# RA register map
Vendor: Renesas; Series: All Chips; File version: x.xx
Registers are 32-bit, read-write, reset 0x0 unless marked. A register's access mark holds for its fields unless they carry their own. Offsets are from the block's base; [hi:lo] are bit positions; {n}, {i} and the like mark numbered series.

## R_DEBUG — Debug Function
Base 0x4001B000
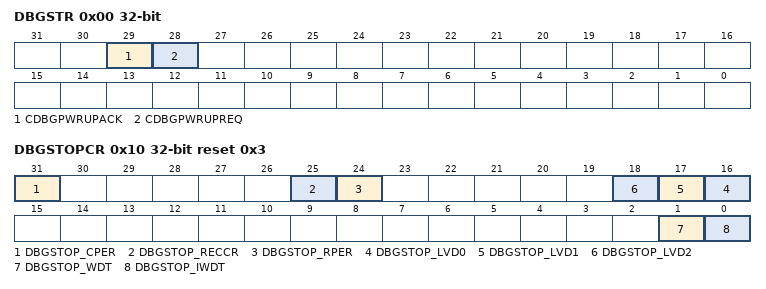
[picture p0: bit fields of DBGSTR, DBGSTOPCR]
0x00 DBGSTR ro — Debug Status Register
  [29] CDBGPWRUPACK — Debug power-up acknowledge
    0=Debug power-up request is not acknowledged; 1=Debug power-up request is acknowledged
  [28] CDBGPWRUPREQ — Debug power-up request
    0=0: OCD is not requesting debug power up; 1=0: OCD is requesting debug power up
0x10 DBGSTOPCR reset 0x3 — Debug Stop Control Register
  [31] DBGSTOP_CPER — Mask bit for Cache SRAM parity error reset/interrupt
    0=Enable Cache SRAM parity error reset/interrupt; 1=Mask Cache SRAM parity error reset/interrupt
  [25] DBGSTOP_RECCR — Mask bit for SRAM ECC error
  [24] DBGSTOP_RPER — Mask bit for SRAM parity error
  [n+16] DBGSTOP_LVD{n} (n=0..2) — Mask bit for LVD reset/interupt
    0=Enable reset/interupt on corresponding LVD; 1=Mask reset/interupt on corresponding LVD
  [1] DBGSTOP_WDT — Mask bit for WDT reset/interrupt
  [0] DBGSTOP_IWDT — Mask bit for IWDT reset/interrupt

## R_DMA — DMA Controller Common
Base 0x40005200
0x00 DMAST 8-bit — DMAC Module Activation Register
  [0] DMST — DMAC Operation Enable
    0=Disabled; 1=Enabled
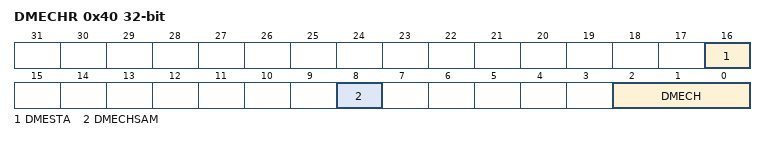
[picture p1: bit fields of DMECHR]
0x40 DMECHR — DMAC Error Channel Register
  [16] DMESTA — DMAC Error Status
    0=No DMA transfer error occurred; 1=DMA transfer error occurred
  [8] DMECHSAM ro — DMAC Error channel Security Attribution Monitor
    0=secure channel; 1=non-secure channel
  [2:0] DMECH ro — DMAC Error channel

## R_DOC — Data Operation Circuit
Base 0x40054100
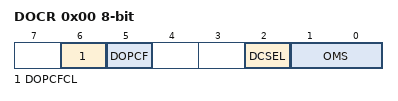
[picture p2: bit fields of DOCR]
0x00 DOCR 8-bit — DOC Control Register
  [6] DOPCFCL — DOPCF Clear
    0=Maintains the DOPCF flag state; 1=Clears the DOPCF flag
  [5] DOPCF ro — Data Operation Circuit Flag
  [2] DCSEL — Detection Condition Select
    0=DOPCF is set when data mismatch is detected; 1=DOPCF is set when data match is detected
  [1:0] OMS — Operating Mode Select
    0=Data comparison mode; 1=Data addition mode; 2=Data subtraction mode; 3=Setting prohibited
0x02 DODIR 16-bit — DOC Data Input Register
  [15:0] DODIR — 16-bit read-write register in which 16-bit data for use in the operations are stored.
0x04 DODSR 16-bit — DOC Data Setting Register
  [15:0] DODSR — This register stores 16-bit data for use as a reference in data comparison mode. This register also stores the results of operations in data addition and data subtraction modes.

## R_DTC — Data Transfer Controller
Base 0x40005400
0x00 DTCCR 8-bit reset 0x8 — DTC Control Register
  [4] RRS — DTC Transfer Information Read Skip Enable.
    0=Do not skip transfer information read; 1=Skip transfer information read when vector numbers match
0x04 DTCVBR — DTC Vector Base Register
  [31:0] DTCVBR — DTC Vector Base Address.Note: A value cannot be set in the lower-order 10 bits. These bits are fixed to 0.
0x0C DTCST 8-bit — DTC Module Start Register
  [0] DTCST — DTC Module Start
    0=DTC module stop; 1=DTC module start
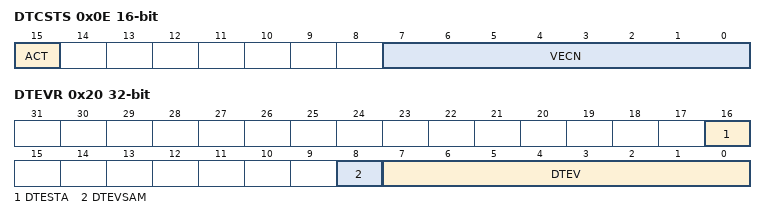
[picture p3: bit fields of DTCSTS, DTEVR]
0x0E DTCSTS 16-bit ro — DTC Status Register
  [15] ACT — DTC Active Flag
    0=DTC transfer operation is not in progress; 1=DTC transfer operation is in progress
  [7:0] VECN — DTC-Activating Vector Number MonitoringThese bits indicate the vector number for the activating source when DTC transfer is in progress.The value is only valid if DTC transfer is in progress (the value of the ACT flag is 1)
0x10 DTCCR_SEC 8-bit reset 0x8 — DTC Control Register for secure Region
  [4] RRSS — DTC Transfer Information Read Skip Enable for Secure
    0=Transfer information read is not skipped; 1=Transfer information read is skipped when vector numbers match
0x14 DTCVBR_SEC — DTC Vector Base Register for secure Region
0x20 DTEVR — DTC Error Vector Register
  [16] DTESTA — DTC Error Status Flag
    0=No DTC transfer error occurred; 1=DTC transfer error occurred
  [8] DTEVSAM ro — DTC Error Vector Number SA Monitor
    0=Secure vector number; 1=Non-Secure vector number
  [7:0] DTEV ro — DTC Error Vector Number
